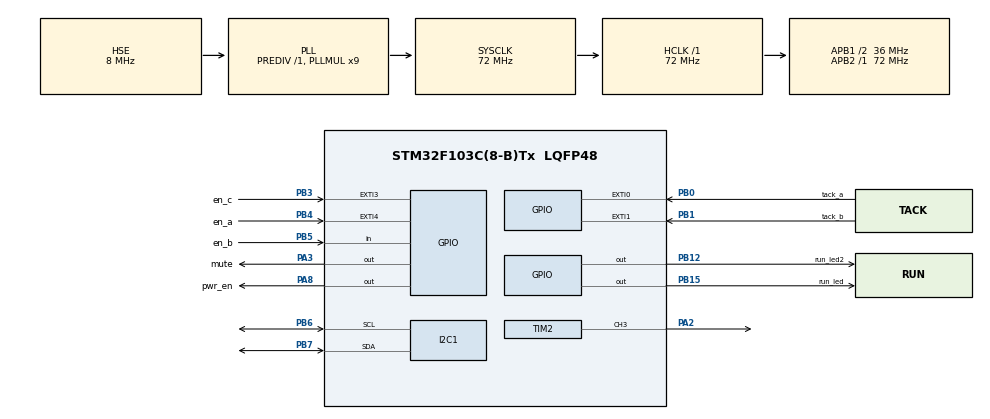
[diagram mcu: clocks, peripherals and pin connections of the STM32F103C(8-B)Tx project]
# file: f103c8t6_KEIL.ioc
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Mcu.Family=STM32F1
Mcu.Name=STM32F103C(8-B)Tx
Mcu.Package=LQFP48
NVIC.EXTI0_IRQn=true\:0\:0\:false\:false\:true\:true\:true\:true
NVIC.EXTI1_IRQn=true\:0\:0\:false\:false\:true\:true\:true\:true
NVIC.EXTI3_IRQn=true\:0\:0\:false\:false\:true\:true\:true\:true
NVIC.EXTI4_IRQn=true\:0\:0\:true\:false\:true\:true\:true\:true
NVIC.PriorityGroup=NVIC_PRIORITYGROUP_4
NVIC.TIM2_IRQn=true\:0\:0\:false\:false\:true\:true\:true\:true
NVIC.TIM3_IRQn=true\:0\:0\:false\:false\:true\:true\:true\:true
PA13.Mode=Serial_Wire
PA13.Signal=SYS_JTMS-SWDIO
PA14.Mode=Serial_Wire
PA14.Signal=SYS_JTCK-SWCLK
PA2.Signal=S_TIM2_CH3
PA3.GPIO_Label=mute
PA3.GPIO_ModeDefaultOutputPP=GPIO_MODE_OUTPUT_PP
PA3.GPIO_PuPd=GPIO_PULLUP
PA3.GPIO_Speed=GPIO_SPEED_FREQ_HIGH
PA3.PinState=GPIO_PIN_SET
PA3.Signal=GPIO_Output
PA8.GPIO_Label=pwr_en
PA8.GPIO_PuPd=GPIO_PULLDOWN
PA8.GPIO_Speed=GPIO_SPEED_FREQ_HIGH
PA8.Signal=GPIO_Output
PB0.GPIO_Label=tack_a
PB0.GPIO_ModeDefaultEXTI=GPIO_MODE_IT_RISING_FALLING
PB0.GPIO_PuPd=GPIO_PULLUP
PB0.Signal=GPXTI0
PB1.GPIO_Label=tack_b
PB1.GPIO_ModeDefaultEXTI=GPIO_MODE_IT_RISING_FALLING
PB1.GPIO_PuPd=GPIO_PULLUP
PB1.Signal=GPXTI1
PB12.GPIO_Label=run_led2
PB12.GPIO_ModeDefaultOutputPP=GPIO_MODE_OUTPUT_PP
PB12.GPIO_PuPd=GPIO_NOPULL
PB12.GPIO_Speed=GPIO_SPEED_FREQ_LOW
PB12.PinState=GPIO_PIN_RESET
PB12.Signal=GPIO_Output
PB15.GPIO_Label=run_led
PB15.GPIO_PuPd=GPIO_PULLUP
PB15.GPIO_Speed=GPIO_SPEED_FREQ_HIGH
PB15.PinState=GPIO_PIN_SET
PB15.Signal=GPIO_Output
PB3.GPIO_Label=en_c
PB3.GPIO_ModeDefaultEXTI=GPIO_MODE_IT_RISING_FALLING
PB3.GPIO_PuPd=GPIO_PULLUP
PB3.Signal=GPXTI3
PB4.GPIO_Label=en_a
PB4.GPIO_ModeDefaultEXTI=GPIO_MODE_IT_RISING
PB4.GPIO_PuPd=GPIO_PULLUP
PB4.Signal=GPXTI4
PB5.GPIO_Label=en_b
PB5.GPIO_PuPd=GPIO_PULLUP
PB5.Signal=GPIO_Input
PB6.Mode=I2C
PB6.Signal=I2C1_SCL
PB7.Mode=I2C
PB7.Signal=I2C1_SDA
PC14-OSC32_IN.Mode=LSE-External-Oscillator
PC14-OSC32_IN.Signal=RCC_OSC32_IN
PC15-OSC32_OUT.Mode=LSE-External-Oscillator
PC15-OSC32_OUT.Signal=RCC_OSC32_OUT
PD0-OSC_IN.Mode=HSE-External-Oscillator
PD0-OSC_IN.Signal=RCC_OSC_IN
PD1-OSC_OUT.Mode=HSE-External-Oscillator
PD1-OSC_OUT.Signal=RCC_OSC_OUT
ProjectManager.HeapSize=0x200
ProjectManager.StackSize=0x400
ProjectManager.TargetToolchain=MDK-ARM V5.32
RCC.AHBFreq_Value=72000000
RCC.APB1CLKDivider=RCC_HCLK_DIV2
RCC.APB1Freq_Value=36000000
RCC.APB1TimFreq_Value=72000000
RCC.APB2Freq_Value=72000000
RCC.APB2TimFreq_Value=72000000
RCC.HCLKFreq_Value=72000000
RCC.PLLMUL=RCC_PLL_MUL9
RCC.PLLSourceVirtual=RCC_PLLSOURCE_HSE
RCC.SYSCLKFreq_VALUE=72000000
RCC.SYSCLKSource=RCC_SYSCLKSOURCE_PLLCLK
RCC.USBFreq_Value=72000000
SH.S_TIM2_CH3.0=TIM2_CH3,PWM Generation3 CH3
TIM2.Channel-PWM\ Generation3\ CH3=TIM_CHANNEL_3
TIM2.Period=0
TIM3.Period=1000-1
TIM3.Prescaler=72-1
VP_TIM2_VS_ClockSourceINT.Mode=Internal
VP_TIM3_VS_ClockSourceINT.Mode=Internal
board=custom

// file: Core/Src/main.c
/* USER CODE BEGIN Header */
/**
  ******************************************************************************
  * @file           : main.c
  * @brief          : Main program body
  ******************************************************************************
  * @attention
  *
  * Copyright (c) 2022 STMicroelectronics.
  * All rights reserved.
  *
  * This software is licensed under terms that can be found in the LICENSE file
  * in the root directory of this software component.
  * If no LICENSE file comes with this software, it is provided AS-IS.
  *
  ******************************************************************************
  */
/* USER CODE END Header */
#include "main.h"

/* USER CODE BEGIN Includes */
#include "mymain.h"
/* USER CODE END Includes */

 I2C_HandleTypeDef hi2c1;

TIM_HandleTypeDef htim2;
TIM_HandleTypeDef htim3;

void SystemClock_Config(void);
static void MX_GPIO_Init(void);
static void MX_I2C1_Init(void);
static void MX_TIM2_Init(void);
static void MX_TIM3_Init(void);

int main(void)
{

  /* MCU Configuration--------------------------------------------------------*/

  /* Reset of all peripherals, Initializes the Flash interface and the Systick. */
  HAL_Init();

  /* Configure the system clock */
  SystemClock_Config();

  /* Initialize all configured peripherals */
  MX_GPIO_Init();
  MX_I2C1_Init();
  MX_TIM2_Init();
  MX_TIM3_Init();
  /* USER CODE BEGIN 2 */
	mymain();
  /* USER CODE END 2 */

  /* Infinite loop */
  while (1)
  {

  }
}

void SystemClock_Config(void)
{
  RCC_OscInitTypeDef RCC_OscInitStruct = {0};
  RCC_ClkInitTypeDef RCC_ClkInitStruct = {0};

  /** Initializes the RCC Oscillators according to the specified parameters
  * in the RCC_OscInitTypeDef structure.
  */
  RCC_OscInitStruct.OscillatorType = RCC_OSCILLATORTYPE_HSE;
  RCC_OscInitStruct.HSEState = RCC_HSE_ON;
  RCC_OscInitStruct.HSEPredivValue = RCC_HSE_PREDIV_DIV1;
  RCC_OscInitStruct.HSIState = RCC_HSI_ON;
  RCC_OscInitStruct.PLL.PLLState = RCC_PLL_ON;
  RCC_OscInitStruct.PLL.PLLSource = RCC_PLLSOURCE_HSE;
  RCC_OscInitStruct.PLL.PLLMUL = RCC_PLL_MUL9;
  if (HAL_RCC_OscConfig(&RCC_OscInitStruct) != HAL_OK)
  {
    Error_Handler();
  }

  /** Initializes the CPU, AHB and APB buses clocks
  */
  RCC_ClkInitStruct.ClockType = RCC_CLOCKTYPE_HCLK|RCC_CLOCKTYPE_SYSCLK
                              |RCC_CLOCKTYPE_PCLK1|RCC_CLOCKTYPE_PCLK2;
  RCC_ClkInitStruct.SYSCLKSource = RCC_SYSCLKSOURCE_PLLCLK;
  RCC_ClkInitStruct.AHBCLKDivider = RCC_SYSCLK_DIV1;
  RCC_ClkInitStruct.APB1CLKDivider = RCC_HCLK_DIV2;
  RCC_ClkInitStruct.APB2CLKDivider = RCC_HCLK_DIV1;

  if (HAL_RCC_ClockConfig(&RCC_ClkInitStruct, FLASH_LATENCY_2) != HAL_OK)
  {
    Error_Handler();
  }
}

static void MX_I2C1_Init(void)
{

  hi2c1.Instance = I2C1;
  hi2c1.Init.ClockSpeed = 100000;
  hi2c1.Init.DutyCycle = I2C_DUTYCYCLE_2;
  hi2c1.Init.OwnAddress1 = 0;
  hi2c1.Init.AddressingMode = I2C_ADDRESSINGMODE_7BIT;
  hi2c1.Init.DualAddressMode = I2C_DUALADDRESS_DISABLE;
  hi2c1.Init.OwnAddress2 = 0;
  hi2c1.Init.GeneralCallMode = I2C_GENERALCALL_DISABLE;
  hi2c1.Init.NoStretchMode = I2C_NOSTRETCH_DISABLE;
  if (HAL_I2C_Init(&hi2c1) != HAL_OK)
  {
    Error_Handler();
  }

}

static void MX_TIM2_Init(void)
{

  TIM_ClockConfigTypeDef sClockSourceConfig = {0};
  TIM_MasterConfigTypeDef sMasterConfig = {0};
  TIM_OC_InitTypeDef sConfigOC = {0};

  htim2.Instance = TIM2;
  htim2.Init.Prescaler = 0;
  htim2.Init.CounterMode = TIM_COUNTERMODE_UP;
  htim2.Init.Period = 0;
  htim2.Init.ClockDivision = TIM_CLOCKDIVISION_DIV1;
  htim2.Init.AutoReloadPreload = TIM_AUTORELOAD_PRELOAD_DISABLE;
  if (HAL_TIM_Base_Init(&htim2) != HAL_OK)
  {
    Error_Handler();
  }
  sClockSourceConfig.ClockSource = TIM_CLOCKSOURCE_INTERNAL;
  if (HAL_TIM_ConfigClockSource(&htim2, &sClockSourceConfig) != HAL_OK)
  {
    Error_Handler();
  }
  if (HAL_TIM_PWM_Init(&htim2) != HAL_OK)
  {
    Error_Handler();
  }
  sMasterConfig.MasterOutputTrigger = TIM_TRGO_RESET;
  sMasterConfig.MasterSlaveMode = TIM_MASTERSLAVEMODE_DISABLE;
  if (HAL_TIMEx_MasterConfigSynchronization(&htim2, &sMasterConfig) != HAL_OK)
  {
    Error_Handler();
  }
  sConfigOC.OCMode = TIM_OCMODE_PWM1;
  sConfigOC.Pulse = 0;
  sConfigOC.OCPolarity = TIM_OCPOLARITY_HIGH;
  sConfigOC.OCFastMode = TIM_OCFAST_DISABLE;
  if (HAL_TIM_PWM_ConfigChannel(&htim2, &sConfigOC, TIM_CHANNEL_3) != HAL_OK)
  {
    Error_Handler();
  }
  HAL_TIM_MspPostInit(&htim2);

}

static void MX_TIM3_Init(void)
{

  TIM_ClockConfigTypeDef sClockSourceConfig = {0};
  TIM_MasterConfigTypeDef sMasterConfig = {0};

  htim3.Instance = TIM3;
  htim3.Init.Prescaler = 72-1;
  htim3.Init.CounterMode = TIM_COUNTERMODE_UP;
  htim3.Init.Period = 1000-1;
  htim3.Init.ClockDivision = TIM_CLOCKDIVISION_DIV1;
  htim3.Init.AutoReloadPreload = TIM_AUTORELOAD_PRELOAD_DISABLE;
  if (HAL_TIM_Base_Init(&htim3) != HAL_OK)
  {
    Error_Handler();
  }
  sClockSourceConfig.ClockSource = TIM_CLOCKSOURCE_INTERNAL;
  if (HAL_TIM_ConfigClockSource(&htim3, &sClockSourceConfig) != HAL_OK)
  {
    Error_Handler();
  }
  sMasterConfig.MasterOutputTrigger = TIM_TRGO_RESET;
  sMasterConfig.MasterSlaveMode = TIM_MASTERSLAVEMODE_DISABLE;
  if (HAL_TIMEx_MasterConfigSynchronization(&htim3, &sMasterConfig) != HAL_OK)
  {
    Error_Handler();
  }

}

static void MX_GPIO_Init(void)
{
  GPIO_InitTypeDef GPIO_InitStruct = {0};

  /* GPIO Ports Clock Enable */
  __HAL_RCC_GPIOC_CLK_ENABLE();
  __HAL_RCC_GPIOD_CLK_ENABLE();
  __HAL_RCC_GPIOA_CLK_ENABLE();
  __HAL_RCC_GPIOB_CLK_ENABLE();

  /*Configure GPIO pin Output Level */
  HAL_GPIO_WritePin(mute_GPIO_Port, mute_Pin, GPIO_PIN_SET);

  /*Configure GPIO pin Output Level */
  HAL_GPIO_WritePin(run_led2_GPIO_Port, run_led2_Pin, GPIO_PIN_RESET);

  /*Configure GPIO pin Output Level */
  HAL_GPIO_WritePin(run_led_GPIO_Port, run_led_Pin, GPIO_PIN_SET);

  /*Configure GPIO pin Output Level */
  HAL_GPIO_WritePin(pwr_en_GPIO_Port, pwr_en_Pin, GPIO_PIN_RESET);

  /*Configure GPIO pin : mute_Pin */
  GPIO_InitStruct.Pin = mute_Pin;
  GPIO_InitStruct.Mode = GPIO_MODE_OUTPUT_PP;
  GPIO_InitStruct.Pull = GPIO_PULLUP;
  GPIO_InitStruct.Speed = GPIO_SPEED_FREQ_HIGH;
  HAL_GPIO_Init(mute_GPIO_Port, &GPIO_InitStruct);

  /*Configure GPIO pins : tack_a_Pin tack_b_Pin en_c_Pin */
  GPIO_InitStruct.Pin = tack_a_Pin|tack_b_Pin|en_c_Pin;
  GPIO_InitStruct.Mode = GPIO_MODE_IT_RISING_FALLING;
  GPIO_InitStruct.Pull = GPIO_PULLUP;
  HAL_GPIO_Init(GPIOB, &GPIO_InitStruct);

  /*Configure GPIO pin : run_led2_Pin */
  GPIO_InitStruct.Pin = run_led2_Pin;
  GPIO_InitStruct.Mode = GPIO_MODE_OUTPUT_PP;
  GPIO_InitStruct.Pull = GPIO_NOPULL;
  GPIO_InitStruct.Speed = GPIO_SPEED_FREQ_LOW;
  HAL_GPIO_Init(run_led2_GPIO_Port, &GPIO_InitStruct);

  /*Configure GPIO pin : run_led_Pin */
  GPIO_InitStruct.Pin = run_led_Pin;
  GPIO_InitStruct.Mode = GPIO_MODE_OUTPUT_PP;
  GPIO_InitStruct.Pull = GPIO_PULLUP;
  GPIO_InitStruct.Speed = GPIO_SPEED_FREQ_HIGH;
  HAL_GPIO_Init(run_led_GPIO_Port, &GPIO_InitStruct);

  /*Configure GPIO pin : pwr_en_Pin */
  GPIO_InitStruct.Pin = pwr_en_Pin;
  GPIO_InitStruct.Mode = GPIO_MODE_OUTPUT_PP;
  GPIO_InitStruct.Pull = GPIO_PULLDOWN;
  GPIO_InitStruct.Speed = GPIO_SPEED_FREQ_HIGH;
  HAL_GPIO_Init(pwr_en_GPIO_Port, &GPIO_InitStruct);

  /*Configure GPIO pin : en_a_Pin */
  GPIO_InitStruct.Pin = en_a_Pin;
  GPIO_InitStruct.Mode = GPIO_MODE_IT_RISING;
  GPIO_InitStruct.Pull = GPIO_PULLUP;
  HAL_GPIO_Init(en_a_GPIO_Port, &GPIO_InitStruct);

  /*Configure GPIO pin : en_b_Pin */
  GPIO_InitStruct.Pin = en_b_Pin;
  GPIO_InitStruct.Mode = GPIO_MODE_INPUT;
  GPIO_InitStruct.Pull = GPIO_PULLUP;
  HAL_GPIO_Init(en_b_GPIO_Port, &GPIO_InitStruct);

  /* EXTI interrupt init*/
  HAL_NVIC_SetPriority(EXTI0_IRQn, 0, 0);
  HAL_NVIC_EnableIRQ(EXTI0_IRQn);

  HAL_NVIC_SetPriority(EXTI1_IRQn, 0, 0);
  HAL_NVIC_EnableIRQ(EXTI1_IRQn);

  HAL_NVIC_SetPriority(EXTI3_IRQn, 0, 0);
  HAL_NVIC_EnableIRQ(EXTI3_IRQn);

  HAL_NVIC_SetPriority(EXTI4_IRQn, 0, 0);
  HAL_NVIC_EnableIRQ(EXTI4_IRQn);

}

void Error_Handler(void)
{
  __disable_irq();
  while (1)
  {
  }
}
